# max32572 register map
Vendor: Maxim-Integrated; Series: ARMCM4; File version: 1.0
CPU: CM4 r2p1, little endian, MPU, FPU, 3 interrupt priority bits
Registers are 32-bit, read-write, reset 0x0 unless marked. A register's access mark holds for its fields unless they carry their own. Offsets are from the block's base; [hi:lo] are bit positions; {n}, {i} and the like mark numbered series; 'fields as' and 'values as' point back to an identical list.

## TRNG — Random Number Generator.
Base 0x4004D000
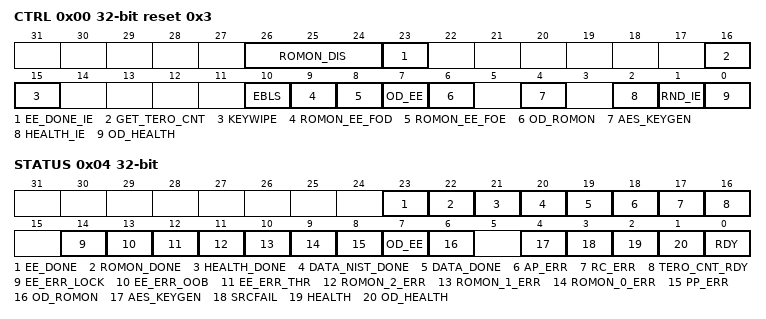
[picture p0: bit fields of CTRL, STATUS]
0x00 CTRL reset 0x3 — TRNG Control Register.
  [26:24] ROMON_DIS — Ring Oscillator Disable.
    0=RO_0 (Ring Oscillator 0.); 1=RO_1 (Ring Oscillator 1.); 2=RO_2 (Ring Oscillator 2.)
  [23] EE_DONE_IE — Entropy Estimator Done Interrupt Enable.
  [16] GET_TERO_CNT — Get Tero Count.
  [15] KEYWIPE — To wipe the Battery Backed key.
  [10] EBLS — Entropy Bit Load Select.
  [9] ROMON_EE_FOD — Ring Oscillator Monitors and Entropy Estimator Freeze on Done.
  [8] ROMON_EE_FOE — Ring Oscillator Monitors and Entropy Estimator Freeze on Error.
  [7] OD_EE — Start entropy estimator on demand test.
  [6] OD_ROMON — Start ring oscillator monitor on demand test.
  [4] AES_KEYGEN — AES Key Generate. When enabled, the key for securing NVSRAM is generated and transferred to the secure key register automatically without user visibility or intervention. This bit is cleared by hardware once the key has been transferred to the secure key register.
  [2] HEALTH_IE — Enable IRQ generation when a health test fails.
  [1] RND_IE — To enable IRQ generation when a new 32-bit Random number is ready.
    0=disable; 1=enable
  [0] OD_HEALTH — Start On-Demand health test.
0x04 STATUS — Data. The content of this register is valid only when RNG_IS = 1. When TRNG is disabled, read returns 0x0000 0000.
  [23] EE_DONE — Entropy Estimator Test Done.
  [22] ROMON_DONE — Ring Oscillator Monitor Test Done.
  [21] HEALTH_DONE — Health Test Done.
  [20] DATA_NIST_DONE — Data NIST register has been loaded with at least 32 new entropy bits.
  [19] DATA_DONE — Data register has been loaded with at least 32 new entropy bits.
  [18] AP_ERR — Adaptive Proportion Error.
  [17] RC_ERR — Repetition Count Error.
  [16] TERO_CNT_RDY — TERO Count Ready.
  [14] EE_ERR_LOCK — Entropy Estimator Lock Error.
  [13] EE_ERR_OOB — Entropy Estimator Out of Bounds Error..
  [12] EE_ERR_THR — Entropy Estimator Threshold Error.
  [11] ROMON_2_ERR — Ring Oscillator 2 Monitor Error.
  [10] ROMON_1_ERR — Ring Oscillator 1 Monitor Error.
  [9] ROMON_0_ERR — Ring Oscillator 0 Monitor Error.
  [8] PP_ERR — Post process error.
  [7] OD_EE — On demand entropy estimator status.
  [6] OD_ROMON — On demand ring oscillator test status.
  [4] AES_KEYGEN — AESKGD.
  [3] SRCFAIL — Entropy source has failed.
  [2] HEALTH — Health test status.
  [1] OD_HEALTH — On-Demand health test status.
  [0] RDY — 32-bit random data is ready to read from TRNG_DATA register. Reading TRNG_DATA when RND_RDY=0 will return all 0's. IRQ is generated when RND_RDY=1 if TRNG_CN.RND_IRQ_EN=1.
    0=Busy (TRNG Busy); 1=Ready (32 bit random data is ready)
0x08 DATA ro — Data. The content of this register is valid only when RNG_IS = 1. When TRNG is disabled, read returns 0x0000 0000.
  [31:0] DATA — Data. The content of this register is valid only when RNG_IS =1. When TNRG is disabled, read returns 0x0000 0000.
0x38 DATA_NIST
  [31:0] DATA — Ring Oscillator 1 Monitor Last Ring Oscillator Count.

## WDT0 — Watchdog Timer 0
Base 0x40003000
Same registers: WDT1 0x40003400
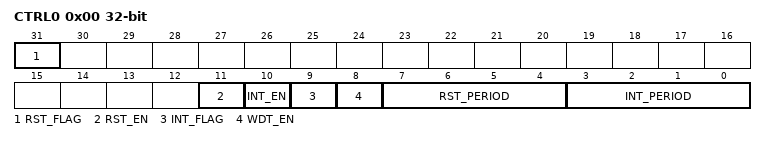
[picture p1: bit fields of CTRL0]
0x00 CTRL0 (reset mask 0x7FFFF000) — Watchdog Timer Control Register.
  [31] RST_FLAG — Watchdog Timer Reset Flag.
    0=noEvent (The event has not occurred.); 1=occurred (The event has occurred.)
  [11] RST_EN — Watchdog Timer Reset Enable.
    0=dis (Disable.); 1=en (Enable.)
  [10] INT_EN — Watchdog Timer Interrupt Enable.
    0=dis (Disable.); 1=en (Enable.)
  [9] INT_FLAG write-1-clears — Watchdog Timer Interrupt Flag.
    0=inactive (No interrupt is pending.); 1=pending (An interrupt is pending.)
  [8] WDT_EN — Watchdog Timer Enable.
    0=dis (Disable.); 1=en (Enable.)
  [7:4] RST_PERIOD — Watchdog Reset Period. The watchdog timer will assert a reset, if enabled, if the CPU does not write the watchdog reset sequence to the WDT_RST register before the watchdog timer has counted this time period since the last timer reset.
    0=wdt2pow31 (2**31 clock cycles.); 1=wdt2pow30 (2**30 clock cycles.); 2=wdt2pow29 (2**29 clock cycles.); 3=wdt2pow28 (2**28 clock cycles.); 4=wdt2pow27 (2^27 clock cycles.); 5=wdt2pow26 (2**26 clock cycles.); 6=wdt2pow25 (2**25 clock cycles.); 7=wdt2pow24 (2**24 clock cycles.); 8=wdt2pow23 (2**23 clock cycles.); 9=wdt2pow22 (2**22 clock cycles.); 10=wdt2pow21 (2**21 clock cycles.); 11=wdt2pow20 (2**20 clock cycles.); 12=wdt2pow19 (2**19 clock cycles.); 13=wdt2pow18 (2**18 clock cycles.); 14=wdt2pow17 (2**17 clock cycles.); 15=wdt2pow16 (2**16 clock cycles.)
  [3:0] INT_PERIOD — Watchdog Interrupt Period. The watchdog timer will assert an interrupt, if enabled, if the CPU does not write the watchdog reset sequence to the WDT_RST register before the watchdog timer has counted this time period since the last timer reset.
    values as RST_PERIOD
0x04 CTRL1 wo — Watchdog Timer Reset Register.
  [7:0] WDT_RST — Writing the watchdog counter 'reset sequence' to this register resets the watchdog counter. If the watchdog count exceeds INT_PERIOD then a watchdog interrupt will occur, if enabled. If the watchdog count exceeds RST_PERIOD then a watchdog reset will occur, if enabled.
    165=seq0 (The first value to be written to reset the WDT.); 90=seq1 (The second value to be written to reset the WDT.)

## SEMA — The Semaphore peripheral allows multiple cores in a system to cooperate when accessing shred resources. The peripheral contains eight semaphores that can be atomically set and cleared. It is left to the discretion of the software architect to decide how and when the semaphores are used and how they are allocated. Existing hardware does not have to be modified for this type of cooperative sharing, and the use of semaphores is exclusively within the software domain.
Base 0x4003E000
{0x0+4i} SEMAPHORES[{i}] (i=0..7) — Read to test and set, returns prior value. Write 0 to clear semaphore.
  [0] sema
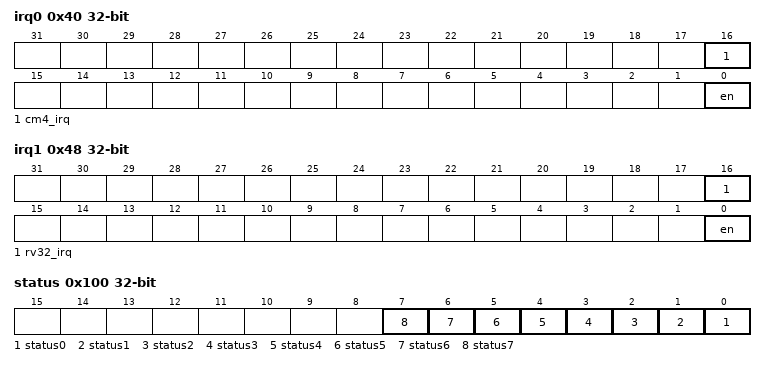
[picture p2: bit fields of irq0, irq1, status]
0x40 irq0 — Semaphore IRQ0 register.
  [16] cm4_irq, [0] en
0x44 mail0 — Semaphore Mailbox 0 register.
  [31:0] data
0x48 irq1 — Semaphore IRQ1 register.
  [16] rv32_irq, [0] en
0x4C mail1 — Semaphore Mailbox 1 register.
  [31:0] data
0x100 status — Semaphore status bits. 0 indicates the semaphore is free, 1 indicates taken.
  [n] status{n} (n=0..7)
